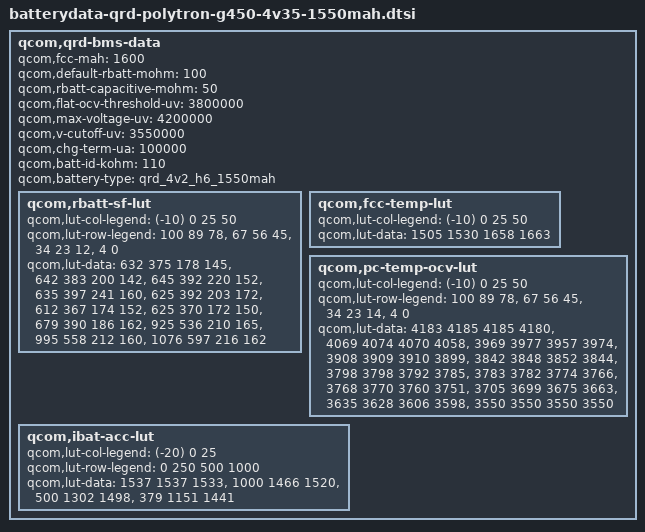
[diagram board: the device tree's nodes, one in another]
/* Copyright (c) 2013, The Linux Foundation. All rights reserved.
 *
 * This program is free software; you can redistribute it and/or modify
 * it under the terms of the GNU General Public License version 2 and
 * only version 2 as published by the Free Software Foundation.
 *
 * This program is distributed in the hope that it will be useful,
 * but WITHOUT ANY WARRANTY; without even the implied warranty of
 * MERCHANTABILITY or FITNESS FOR A PARTICULAR PURPOSE.  See the
 * GNU General Public License for more details.
 */

qcom,qrd-bms-data {
	qcom,fcc-mah = <1600>;	/*<1550>;*/
	qcom,default-rbatt-mohm = <100>;
	qcom,rbatt-capacitive-mohm = <50>;
	qcom,flat-ocv-threshold-uv = <3800000>;
	qcom,max-voltage-uv = <4200000>;
	qcom,v-cutoff-uv = <3550000>;/*oem modify to 3450000*/
	qcom,chg-term-ua = <100000>;
	qcom,batt-id-kohm = <110>;
	qcom,battery-type = "qrd_4v2_h6_1550mah";

	
	qcom,rbatt-sf-lut {
		qcom,lut-col-legend = <(-10) 0 25 50>;
		qcom,lut-row-legend =  <100 89 78>,
				<67 56 45>,
				<34 23 12>,
				<4 0>;

		qcom,lut-data = 		
			/*<475	223	193	133>,
			<403	380	193	133>,
			<503	368	220	160>,
			<490	363	240	180>,
			<473	350	203	140>,
			<455	333	185	125>,
			<463	338	195	135>,
			<498	358	198	138>,
			<543	390	198	138>,
			<543	390	198	139>,
			<563	310	308	250>;*//*4v35 battery parameter*/	

			<632	375	178	145>,/*4v2 battery parameter*/	
			<642	383	200	142>,
			<645	392	220	152>,
			<635	397	241	160>,
			<625	392	203	172>,
			<612	367	174	152>,
			<625	370	172	150>,
			<679	390	186	162>,
			<925	536	210	165>,
			<995	558	212	160>,
			<1076	597	216	162>;			
	};


	qcom,fcc-temp-lut {
		qcom,lut-col-legend = <(-10) 0 25 50>;
		/*qcom,lut-data = <1985 2000 2008 1968>;*/
		qcom,lut-data = <1505 1530 1658 1663>;
	};

	qcom,pc-temp-ocv-lut {
		qcom,lut-col-legend = <(-10) 0 25 50>;
		qcom,lut-row-legend =  <100 89 78>,
				<67 56 45>,
				<34 23 14>,
				<4 0>;
				
		qcom,lut-data = 
		<4183	4185	4185	4180>,/*4v2 battery parameter*/	
		//<4175	4175	4177	4175>,
		<4069	4074	4070	4058>,
		<3969	3977	3957	3974>,		
		<3908	3909	3910	3899>,	 
		<3842	3848	3852	3844>,	 
		<3798	3798	3792	3785>,	 
		<3783	3782	3774	3766>,	 
		<3768	3770	3760	3751>,	 
		<3705	3699	3675	3663>,	 
		<3635	3628	3606	3598>,	 
		<3550	3550	3550	3550>;
		
		/*<4290	4285	4320	4320>,*//*4v35 battery parameter*/	 
		/*<4181	4182	4189	4193>,
		<4090	4087	4089	4089>,
		<4008	4008	4010	4010>,		
		<3928	3943	3963	3963>,	 
		<3874	3881	3881	3881>,	 
		<3809	3834	3819	3819>,	 
		<3768	3785	3784	3784>,	 
		<3733	3756	3759	3759>,	 
		<3701	3723	3736	3736>,	 
		<3624	3643	3683	3683>,	 
		<3550	3550	3550	3550>;*/	
	
	};

		qcom,ibat-acc-lut {
		qcom,lut-col-legend = <(-20) 0 25>;
		qcom,lut-row-legend = <0 250 500 1000>;
		qcom,lut-data = <1537 1537 1533>,
				<1000 1466 1520>,
				<500 1302 1498>,
				<379 1151 1441>;
	};

};
